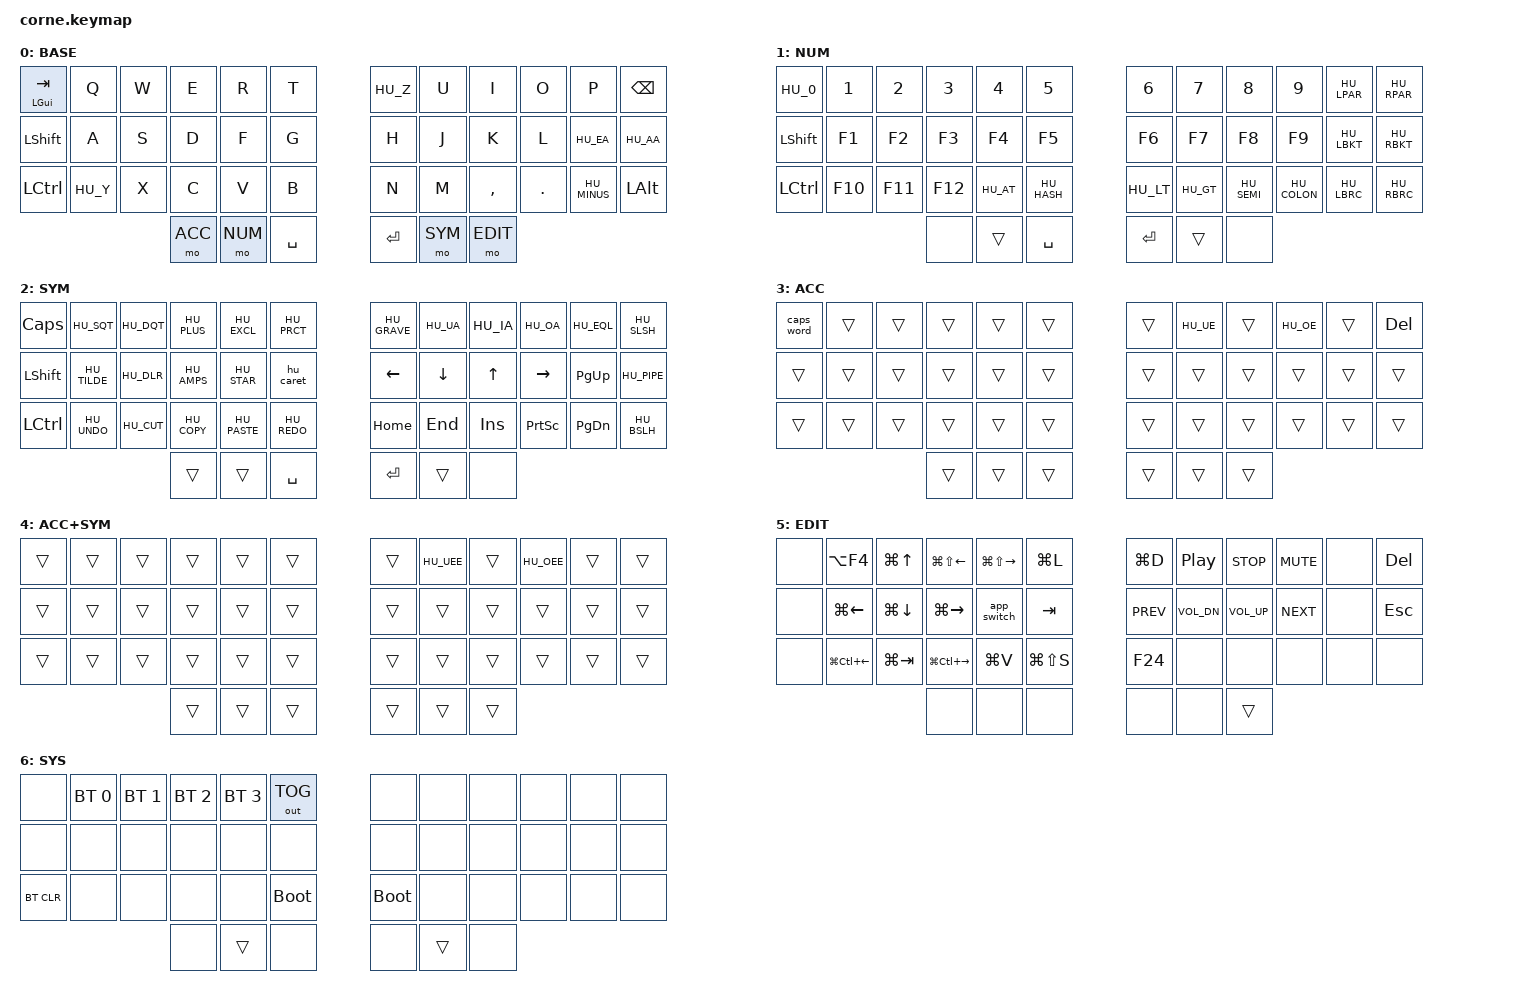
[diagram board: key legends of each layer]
/*
 * Copyright (c) 2020 The ZMK Contributors
 *
 * SPDX-License-Identifier: MIT
 *
 * Corne 3x6, Hungarian OS layout (QWERTZ).
 * Layers: BASE, NUM (left middle thumb), SYM (right middle thumb),
 *         ACC (left outer thumb), DACC (ACC + SYM),
 *         EDIT (right outer thumb): Del, Esc, media, shortcuts,
 *         SYS (NUM + SYM): Bluetooth, USB/BT, bootloader (two thumbs -> no accidents).
 *
 * Accents (á é are on the base layer):
 *   SYM + I / O / U  -> í ó ú
 *   ACC + O / U      -> ö ü
 *   ACC + SYM + O/U  -> ő ű
 */

#include <../boards/shields/corne/boards/nice_nano.overlay>
#include <behaviors.dtsi>
#include <dt-bindings/zmk/bt.h>
#include <dt-bindings/zmk/keys.h>
#include <dt-bindings/zmk/outputs.h>
#include "hu_keys.h"

#define BASE 0
#define NUM  1
#define SYM  2
#define ACC  3
#define DACC 4
#define EDIT 5
#define SYS  6

/* Caps Word on the Hungarian layout: _ is Shift + the "-" key (FSLH) and 0 is
 * GRAVE, so those keep the word going too. Accented letters end it (ZMK only
 * shifts A-Z). */
&caps_word {
    continue-list = <LS(FSLH) GRAVE BSPC DEL>;
};

/ {
    macros {
        /* AltGr + key with AltGr sent in its own report and short pauses.
         * &kp RA(X) sends both in one report: fine locally, but over Remote
         * Desktop the AltGr sometimes arrives late and the plain key is typed. */
        ag: altgr_tap {
            compatible = "zmk,behavior-macro-one-param";
            #binding-cells = <1>;
            wait-ms = <15>;
            tap-ms = <15>;
            bindings = <&macro_press &kp RALT>, <&macro_param_1to1>,
                       <&macro_tap &kp MACRO_PLACEHOLDER>, <&macro_release &kp RALT>;
        };
        /* ^ is a dead key on Windows HU: AltGr+3 then Space makes it appear at once.
         * (~ and ` are plain AltGr keys there, see hu_keys.h) */
        hu_caret: hu_caret {
            compatible = "zmk,behavior-macro";
            #binding-cells = <0>;
            wait-ms = <15>;
            tap-ms = <15>;
            bindings = <&macro_press &kp RALT>, <&macro_tap &kp N3>,
                       <&macro_release &kp RALT>, <&macro_tap &kp SPACE>;
        };
        /* Alt+Tab that keeps Alt held while the key is held:
         * tap = previous app, hold + tap Tab (G) = walk the switcher, release = switch */
        app_switch: app_switch {
            compatible = "zmk,behavior-macro";
            #binding-cells = <0>;
            bindings = <&macro_press &kp LALT>, <&macro_tap &kp TAB>,
                       <&macro_pause_for_release>, <&macro_release &kp LALT>;
        };
    };

    behaviors {
        /* Tab on tap, Win on hold. tap-preferred: Win only after the key is
         * held past the tapping term, so a fast Tab + letter never becomes
         * a Win shortcut (Win+L would lock the PC). */
        tab_gui: tab_gui {
            compatible = "zmk,behavior-hold-tap";
            #binding-cells = <2>;
            flavor = "tap-preferred";
            tapping-term-ms = <200>;
            quick-tap-ms = <150>;
            bindings = <&kp>, <&kp>;
        };
    };

    conditional_layers {
        compatible = "zmk,conditional-layers";
        dacc_cond {
            if-layers = <ACC SYM>;
            then-layer = <DACC>;
        };
        sys_cond {
            if-layers = <NUM SYM>;
            then-layer = <SYS>;
        };
    };

    keymap {
        compatible = "zmk,keymap";

        base_layer {
            display-name = "BASE";
            // ,-----------------------------------------.   ,-----------------------------------------.
            // |TAB/WIN|  Q  |  W  |  E  |  R  |  T  |   |  Z  |  U  |  I  |  O  |  P  | BKSP |
            // | SHFT |  A  |  S  |  D  |  F  |  G  |   |  H  |  J  |  K  |  L  |  É  |  Á   |
            // | CTRL |  Y  |  X  |  C  |  V  |  B  |   |  N  |  M  |  ,  |  .  |  -  | ALT  |
            // `------------------| ACC | NUM | SPC |   | ENT | SYM | EDIT|-----------------'
            bindings = <
&tab_gui LGUI TAB  &kp Q  &kp W  &kp E     &kp R    &kp T        HU_Z     &kp U    &kp I      &kp O    &kp P     &kp BSPC
&kp LSHFT          &kp A  &kp S  &kp D     &kp F    &kp G        &kp H    &kp J    &kp K      &kp L    HU_EA     HU_AA
&kp LCTRL          HU_Y   &kp X  &kp C     &kp V    &kp B        &kp N    &kp M    &kp COMMA  &kp DOT  HU_MINUS  &kp LALT
                                 &mo ACC   &mo NUM  &kp SPACE    &kp RET  &mo SYM  &mo EDIT
            >;
        };

        num_layer {
            display-name = "NUM";
            // Old LWR layer; media / PrtSc / Caps replaced by @ # < > ; :
            // ,-----------------------------------------.   ,-----------------------------------------.
            // |  0   |  1  |  2  |  3  |  4  |  5  |   |  6  |  7  |  8  |  9  |  (  |  )   |
            // | SHFT | F1  | F2  | F3  | F4  | F5  |   | F6  | F7  | F8  | F9  |  [  |  ]   |
            // | CTRL | F10 | F11 | F12 |  @  |  #  |   |  <  |  >  |  ;  |  :  |  {  |  }   |
            // `------------------|     | ### | SPC |   | ENT |     |     |-----------------'
            bindings = <
HU_0       &kp N1   &kp N2   &kp N3   &kp N4   &kp N5       &kp N6   &kp N7   &kp N8   &kp N9   HU_LPAR  HU_RPAR
&kp LSHFT  &kp F1   &kp F2   &kp F3   &kp F4   &kp F5       &kp F6   &kp F7   &kp F8   &kp F9   HU_LBKT  HU_RBKT
&kp LCTRL  &kp F10  &kp F11  &kp F12  HU_AT    HU_HASH      HU_LT    HU_GT    HU_SEMI  HU_COLON HU_LBRC  HU_RBRC
                             &none    &trans   &kp SPACE    &kp RET  &trans   &none
            >;
        };

        sym_layer {
            display-name = "SYM";
            // ,-----------------------------------------.   ,-----------------------------------------.
            // | CAPS |  '  |  "  |  +  |  !  |  %  |   |  `  |  Ú  |  Í  |  Ó  |  =  |  /   |
            // | SHFT |  ~  |  $  |  &  |  *  |  ^  |   | LEFT| DOWN|  UP | RGHT| PGUP|  |   |
            // | CTRL | UNDO| CUT | COPY|PASTE| REDO|   | HOME| END | INS | PSCR| PGDN|  \   |
            // `------------------|(ACC)|     | SPC |   | ENT | ### |     |-----------------'
            //   ACC + SYM = DACC layer (ő ű); arrows on vim h j k l
            bindings = <
&kp CAPS   HU_SQT    HU_DQT    HU_PLUS    HU_EXCL    HU_PRCT      HU_GRAVE    HU_UA        HU_IA        HU_OA        HU_EQL        HU_SLSH
&kp LSHFT  HU_TILDE  HU_DLR    HU_AMPS    HU_STAR    &hu_caret    &kp LEFT    &kp DOWN     &kp UP       &kp RIGHT    &kp PG_UP     HU_PIPE
&kp LCTRL  HU_UNDO   HU_CUT    HU_COPY    HU_PASTE   HU_REDO      &kp HOME    &kp END      &kp INS      &kp PSCRN    &kp PG_DN     HU_BSLH
                               &trans     &trans     &kp SPACE    &kp RET     &trans       &none
            >;
        };

        acc_layer {
            display-name = "ACC";
            // Caps Word on Tab, umlauts on their own vowel, Del on Backspace; the rest falls through.
            // ,-----------------------------------------.   ,-----------------------------------------.
            // |CapsW |     |     |     |     |     |   |     |  Ü  |     |  Ö  |     | DEL  |
            // `------------------| ### |     |     |   |     |(SYM)|     |-----------------'
            bindings = <
&caps_word &trans &trans &trans &trans  &trans       &trans  HU_UE   &trans  HU_OE   &trans  &kp DEL
&trans  &trans  &trans  &trans  &trans  &trans       &trans  &trans  &trans  &trans  &trans  &trans
&trans  &trans  &trans  &trans  &trans  &trans       &trans  &trans  &trans  &trans  &trans  &trans
                        &trans  &trans  &trans       &trans  &trans  &trans
            >;
        };

        dacc_layer {
            display-name = "ACC+SYM";
            // ACC + SYM: double acute on O / U, the rest falls through to ACC.
            // ,-----------------------------------------.   ,-----------------------------------------.
            // |      |     |     |     |     |     |   |     |  Ű  |     |  Ő  |     |      |
            bindings = <
&trans  &trans  &trans  &trans  &trans  &trans       &trans  HU_UEE  &trans  HU_OEE  &trans  &trans
&trans  &trans  &trans  &trans  &trans  &trans       &trans  &trans  &trans  &trans  &trans  &trans
&trans  &trans  &trans  &trans  &trans  &trans       &trans  &trans  &trans  &trans  &trans  &trans
                        &trans  &trans  &trans       &trans  &trans  &trans
            >;
        };

        edit_layer {
            display-name = "EDIT";
            // Right outer thumb held. Left hand: windows / desktops, right hand: media.
            // ,-----------------------------------------.   ,-----------------------------------------.
            // |      |ALTF4| MAX |<-MON|MON->| LOCK|   | DESK| PLAY| STOP| MUTE|     | DEL  |
            // |      |SNAPL| MIN |SNAPR| APPS| TAB |   | PREV| VOL-| VOL+| NEXT|     | ESC  |
            // |      |<-DSK| TASK|DSK->| CLIP| SNIP|   | INFO|     |     |     |     |      |
            // `------------------|     |     |     |   |     |     | ### |-----------------'
            //   MAX/MIN/SNAP = Win+arrows, MON = Win+Shift+arrow (move window to other monitor),
            //   APPS = Alt+Tab switcher (hold, tap TAB to walk), DSK = Win+Ctrl+arrow (virtual desktop),
            //   TASK = Win+Tab, LOCK = Win+L, DESK = Win+D, CLIP = Win+V, SNIP = Win+Shift+S,
            //   INFO = F24 -> toggles the layout overlay on the PC (overlay/layout_overlay.ps1).
            bindings = <
&none  &kp LA(F4)        &kp LG(UP)    &kp LG(LS(LEFT))   &kp LG(LS(RIGHT))  &kp LG(L)          &kp LG(D)   &kp C_PP      &kp C_STOP    &kp C_MUTE  &none  &kp DEL
&none  &kp LG(LEFT)      &kp LG(DOWN)  &kp LG(RIGHT)      &app_switch        &kp TAB            &kp C_PREV  &kp C_VOL_DN  &kp C_VOL_UP  &kp C_NEXT  &none  &kp ESC
&none  &kp LG(LC(LEFT))  &kp LG(TAB)   &kp LG(LC(RIGHT))  &kp LG(V)          &kp LG(LS(S))      &kp F24     &none         &none         &none       &none  &none
                                       &none              &none              &none              &none       &none         &trans
            >;
        };

        sys_layer {
            display-name = "SYS";
            // NUM + SYM held together. BOOT on both halves (each half flashes itself).
            // ,-----------------------------------------.   ,-----------------------------------------.
            // |      | BT0 | BT1 | BT2 | BT3 |USB/BT|   |     |     |     |     |     |      |
            // |      |     |     |     |     |     |   |     |     |     |     |     |      |
            // |BTCLR |     |     |     |     | BOOT|   | BOOT|     |     |     |     |      |
            // `------------------|     | ### |     |   |     | ### |     |-----------------'
            bindings = <
&none        &bt BT_SEL 0  &bt BT_SEL 1  &bt BT_SEL 2  &bt BT_SEL 3  &out OUT_TOG    &none        &none  &none  &none  &none  &none
&none        &none         &none         &none         &none         &none           &none        &none  &none  &none  &none  &none
&bt BT_CLR   &none         &none         &none         &none         &bootloader     &bootloader  &none  &none  &none  &none  &none
                                         &none         &trans        &none           &none        &trans &none
            >;
        };
    };
};
